AUTOSAR XML (schema 4-0-3)
package /ComponentTypes
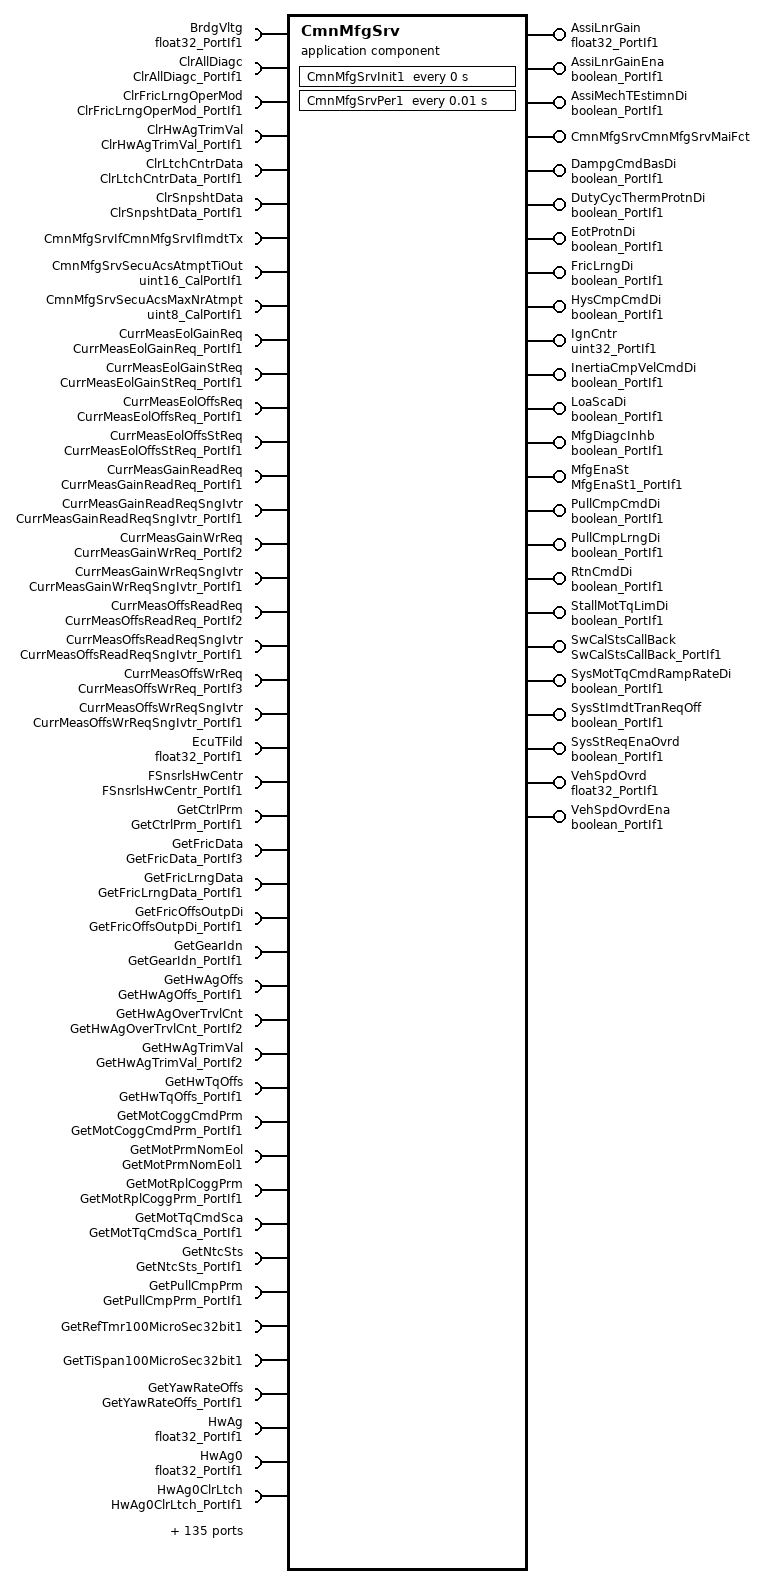
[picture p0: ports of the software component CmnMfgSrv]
  application sw component type CmnMfgSrv
    24 x provide port:
      AssiLnrGain: nonqueued-sender-com-spec{data-element=Val, init-value=0}, provided-interface=float32_PortIf1
      AssiLnrGainEna: nonqueued-sender-com-spec{data-element=Logl, init-value=0}, provided-interface=boolean_PortIf1
      AssiMechTEstimnDi: nonqueued-sender-com-spec{data-element=Logl, init-value=0}, provided-interface=boolean_PortIf1
      CmnMfgSrvCmnMfgSrvMaiFct: server-com-spec{operation=Oper, queue-length=1}, provided-interface=CmnMfgSrvCmnMfgSrvMaiFct
      DampgCmdBasDi: nonqueued-sender-com-spec{data-element=Logl, init-value=0}, provided-interface=boolean_PortIf1
      DutyCycThermProtnDi: nonqueued-sender-com-spec{data-element=Logl, init-value=0}, provided-interface=boolean_PortIf1
      EotProtnDi: nonqueued-sender-com-spec{data-element=Logl, init-value=0}, provided-interface=boolean_PortIf1
      FricLrngDi: nonqueued-sender-com-spec{data-element=Logl, init-value=0}, provided-interface=boolean_PortIf1
      HysCmpCmdDi: nonqueued-sender-com-spec{data-element=Logl, init-value=0}, provided-interface=boolean_PortIf1
      IgnCntr: nonqueued-sender-com-spec{data-element=Val, init-value=0}, provided-interface=uint32_PortIf1
      InertiaCmpVelCmdDi: nonqueued-sender-com-spec{data-element=Logl, init-value=0}, provided-interface=boolean_PortIf1
      LoaScaDi: nonqueued-sender-com-spec{data-element=Logl, init-value=0}, provided-interface=boolean_PortIf1
      MfgDiagcInhb: nonqueued-sender-com-spec{data-element=Logl, init-value=0}, provided-interface=boolean_PortIf1
      MfgEnaSt: nonqueued-sender-com-spec{data-element=Val, init-value=0}, provided-interface=MfgEnaSt1_PortIf1
      PullCmpCmdDi: nonqueued-sender-com-spec{data-element=Logl, init-value=0}, provided-interface=boolean_PortIf1
      PullCmpLrngDi: nonqueued-sender-com-spec{data-element=Logl, init-value=0}, provided-interface=boolean_PortIf1
      RtnCmdDi: nonqueued-sender-com-spec{data-element=Logl, init-value=0}, provided-interface=boolean_PortIf1
      StallMotTqLimDi: nonqueued-sender-com-spec{data-element=Logl, init-value=0}, provided-interface=boolean_PortIf1
      SwCalStsCallBack: server-com-spec{operation=Oper, queue-length=1}, provided-interface=SwCalStsCallBack_PortIf1
      SysMotTqCmdRampRateDi: nonqueued-sender-com-spec{data-element=Logl, init-value=0}, provided-interface=boolean_PortIf1
      SysStImdtTranReqOff: nonqueued-sender-com-spec{data-element=Logl, init-value=0}, provided-interface=boolean_PortIf1
      SysStReqEnaOvrd: nonqueued-sender-com-spec{data-element=Logl, init-value=0}, provided-interface=boolean_PortIf1
      VehSpdOvrd: nonqueued-sender-com-spec{data-element=Val, init-value=0}, provided-interface=float32_PortIf1
      VehSpdOvrdEna: nonqueued-sender-com-spec{data-element=Logl, init-value=0}, provided-interface=boolean_PortIf1
    183 x require port:
      BrdgVltg: nonqueued-receiver-com-spec{data-element=Val, filter=data-filter-type=ALWAYS, init-value=6}, required-interface=float32_PortIf1
      ClrAllDiagc: client-com-spec=Oper, required-interface=ClrAllDiagc_PortIf1
      ClrFricLrngOperMod: client-com-spec=Oper, required-interface=ClrFricLrngOperMod_PortIf1
      ClrHwAgTrimVal: client-com-spec=Oper, required-interface=ClrHwAgTrimVal_PortIf1
      ClrLtchCntrData: client-com-spec=Oper, required-interface=ClrLtchCntrData_PortIf1
      ClrSnpshtData: client-com-spec=Oper, required-interface=ClrSnpshtData_PortIf1
      CmnMfgSrvIfCmnMfgSrvIfImdtTx: client-com-spec=Oper, required-interface=CmnMfgSrvIfCmnMfgSrvIfImdtTx
      CmnMfgSrvSecuAcsAtmptTiOut: parameter-require-com-spec{init-value=10000, parameter=Val}, required-interface=uint16_CalPortIf1
      CmnMfgSrvSecuAcsMaxNrAtmpt: parameter-require-com-spec{init-value=2, parameter=Val}, required-interface=uint8_CalPortIf1
      CurrMeasEolGainReq: client-com-spec=Oper, required-interface=CurrMeasEolGainReq_PortIf1
      CurrMeasEolGainStReq: client-com-spec=Oper, required-interface=CurrMeasEolGainStReq_PortIf1
      CurrMeasEolOffsReq: client-com-spec=Oper, required-interface=CurrMeasEolOffsReq_PortIf1
      CurrMeasEolOffsStReq: client-com-spec=Oper, required-interface=CurrMeasEolOffsStReq_PortIf1
      CurrMeasGainReadReq: client-com-spec=Oper, required-interface=CurrMeasGainReadReq_PortIf1
      CurrMeasGainReadReqSngIvtr: client-com-spec=Oper, required-interface=CurrMeasGainReadReqSngIvtr_PortIf1
      CurrMeasGainWrReq: client-com-spec=Oper, required-interface=CurrMeasGainWrReq_PortIf2
      CurrMeasGainWrReqSngIvtr: client-com-spec=Oper, required-interface=CurrMeasGainWrReqSngIvtr_PortIf1
      CurrMeasOffsReadReq: client-com-spec=Oper, required-interface=CurrMeasOffsReadReq_PortIf2
      CurrMeasOffsReadReqSngIvtr: client-com-spec=Oper, required-interface=CurrMeasOffsReadReqSngIvtr_PortIf1
      CurrMeasOffsWrReq: client-com-spec=Oper, required-interface=CurrMeasOffsWrReq_PortIf3
      CurrMeasOffsWrReqSngIvtr: client-com-spec=Oper, required-interface=CurrMeasOffsWrReqSngIvtr_PortIf1
      EcuTFild: nonqueued-receiver-com-spec{data-element=Val, filter=data-filter-type=ALWAYS, init-value=25}, required-interface=float32_PortIf1
      FSnsrlsHwCentr: client-com-spec=Oper, required-interface=FSnsrlsHwCentr_PortIf1
      GetCtrlPrm: client-com-spec=Oper, required-interface=GetCtrlPrm_PortIf1
      GetFricData: client-com-spec=Oper, required-interface=GetFricData_PortIf3
      GetFricLrngData: client-com-spec=Oper, required-interface=GetFricLrngData_PortIf1
      GetFricOffsOutpDi: client-com-spec=Oper, required-interface=GetFricOffsOutpDi_PortIf1
      GetGearIdn: client-com-spec=Oper, required-interface=GetGearIdn_PortIf1
      GetHwAgOffs: client-com-spec=Oper, required-interface=GetHwAgOffs_PortIf1
      GetHwAgOverTrvlCnt: client-com-spec=Oper, required-interface=GetHwAgOverTrvlCnt_PortIf2
      GetHwAgTrimVal: client-com-spec=Oper, required-interface=GetHwAgTrimVal_PortIf2
      GetHwTqOffs: client-com-spec=Oper, required-interface=GetHwTqOffs_PortIf1
      GetMotCoggCmdPrm: client-com-spec=Oper, required-interface=GetMotCoggCmdPrm_PortIf1
      GetMotPrmNomEol: client-com-spec=Oper, required-interface=GetMotPrmNomEol1
      GetMotRplCoggPrm: client-com-spec=Oper, required-interface=GetMotRplCoggPrm_PortIf1
      GetMotTqCmdSca: client-com-spec=Oper, required-interface=GetMotTqCmdSca_PortIf1
      GetNtcSts: client-com-spec=Oper, required-interface=GetNtcSts_PortIf1
      GetPullCmpPrm: client-com-spec=Oper, required-interface=GetPullCmpPrm_PortIf1
      GetRefTmr100MicroSec32bit1: client-com-spec=Oper, required-interface=GetRefTmr100MicroSec32bit1
      GetTiSpan100MicroSec32bit1: client-com-spec=Oper, required-interface=GetTiSpan100MicroSec32bit1
      GetYawRateOffs: client-com-spec=Oper, required-interface=GetYawRateOffs_PortIf1
      HwAg: nonqueued-receiver-com-spec{data-element=Val, filter=data-filter-type=ALWAYS, init-value=0}, required-interface=float32_PortIf1
      HwAg0: nonqueued-receiver-com-spec{data-element=Val, filter=data-filter-type=ALWAYS, init-value=0}, required-interface=float32_PortIf1
      HwAg0ClrLtch: client-com-spec=Oper, required-interface=HwAg0ClrLtch_PortIf1
      HwAg0MeasHwAg0AutoTrim: client-com-spec=Oper, required-interface=HwAg0MeasHwAg0AutoTrim1
      HwAg0MeasHwAg0ClrTrim: client-com-spec=Oper, required-interface=HwAg0MeasHwAg0ClrTrim1
      HwAg0MeasHwAg0ReadTrim: client-com-spec=Oper, required-interface=HwAg0MeasHwAg0ReadTrim2
      HwAg0MeasHwAg0TrimPrfmdSts: client-com-spec=Oper, required-interface=HwAg0MeasHwAg0TrimPrfmdSts2
      HwAg0MeasHwAg0WrTrim: client-com-spec=Oper, required-interface=HwAg0MeasHwAg0WrTrim2
      HwAg1: nonqueued-receiver-com-spec{data-element=Val, filter=data-filter-type=ALWAYS, init-value=0}, required-interface=float32_PortIf1
      HwAg1ClrLtch: client-com-spec=Oper, required-interface=HwAg1ClrLtch_PortIf1
      HwAg1MeasHwAg1AutoTrim: client-com-spec=Oper, required-interface=HwAg1MeasHwAg1AutoTrim1
      HwAg1MeasHwAg1ClrTrim: client-com-spec=Oper, required-interface=HwAg1MeasHwAg1ClrTrim1
      HwAg1MeasHwAg1ReadTrim: client-com-spec=Oper, required-interface=HwAg1MeasHwAg1ReadTrim2
      HwAg1MeasHwAg1TrimPrfmdSts: client-com-spec=Oper, required-interface=HwAg1MeasHwAg1TrimPrfmdSts2
      HwAg1MeasHwAg1WrTrim: client-com-spec=Oper, required-interface=HwAg1MeasHwAg1WrTrim2
      HwTq: nonqueued-receiver-com-spec{data-element=Val, filter=data-filter-type=ALWAYS, init-value=0}, required-interface=float32_PortIf1
      HwTq0: nonqueued-receiver-com-spec{data-element=Val, filter=data-filter-type=ALWAYS, init-value=0}, required-interface=float32_PortIf1
      HwTq0MeasHwTq0AutTrim: client-com-spec=Oper, required-interface=HwTq0MeasHwTq0AutTrim_PortIf1
      HwTq0MeasHwTq0ClrTrim: client-com-spec=Oper, required-interface=HwTq0MeasHwTq0ClrTrim_PortIf1
      HwTq0MeasHwTq0ReadTrim: client-com-spec=Oper, required-interface=HwTq0MeasHwTq0ReadTrim_PortIf1
      HwTq0MeasHwTq0TrimPrfmdSts: client-com-spec=Oper, required-interface=HwTq0MeasHwTq0TrimPrfmdSts_PortIf1
      HwTq0MeasHwTq0WrTrim: client-com-spec=Oper, required-interface=HwTq0MeasHwTq0WrTrim_PortIf1
      HwTq1: nonqueued-receiver-com-spec{data-element=Val, filter=data-filter-type=ALWAYS, init-value=0}, required-interface=float32_PortIf1
      HwTq1MeasHwTq1AutTrim: client-com-spec=Oper, required-interface=HwTq1MeasHwTq1AutTrim_PortIf1
      HwTq1MeasHwTq1ClrTrim: client-com-spec=Oper, required-interface=HwTq1MeasHwTq1ClrTrim_PortIf1
      HwTq1MeasHwTq1ReadTrim: client-com-spec=Oper, required-interface=HwTq1MeasHwTq1ReadTrim_PortIf1
      HwTq1MeasHwTq1TrimPrfmdSts: client-com-spec=Oper, required-interface=HwTq1MeasHwTq1TrimPrfmdSts_PortIf1
      HwTq1MeasHwTq1WrTrim: client-com-spec=Oper, required-interface=HwTq1MeasHwTq1WrTrim_PortIf1
      HwTq2: nonqueued-receiver-com-spec{data-element=Val, filter=data-filter-type=ALWAYS, init-value=0}, required-interface=float32_PortIf1
      HwTq2MeasHwTq2AutTrim: client-com-spec=Oper, required-interface=HwTq2MeasHwTq2AutTrim_PortIf1
      HwTq2MeasHwTq2ClrTrim: client-com-spec=Oper, required-interface=HwTq2MeasHwTq2ClrTrim_PortIf1
      HwTq2MeasHwTq2ReadTrim: client-com-spec=Oper, required-interface=HwTq2MeasHwTq2ReadTrim_PortIf1
      HwTq2MeasHwTq2TrimPrfmdSts: client-com-spec=Oper, required-interface=HwTq2MeasHwTq2TrimPrfmdSts_PortIf1
      HwTq2MeasHwTq2WrTrim: client-com-spec=Oper, required-interface=HwTq2MeasHwTq2WrTrim_PortIf1
      HwTq3: nonqueued-receiver-com-spec{data-element=Val, filter=data-filter-type=ALWAYS, init-value=0}, required-interface=float32_PortIf1
      HwTq3MeasHwTq3AutTrim: client-com-spec=Oper, required-interface=HwTq3MeasHwTq3AutTrim_PortIf1
      HwTq3MeasHwTq3ClrTrim: client-com-spec=Oper, required-interface=HwTq3MeasHwTq3ClrTrim_PortIf1
      HwTq3MeasHwTq3ReadTrim: client-com-spec=Oper, required-interface=HwTq3MeasHwTq3ReadTrim_PortIf1
      HwTq3MeasHwTq3TrimPrfmdSts: client-com-spec=Oper, required-interface=HwTq3MeasHwTq3TrimPrfmdSts_PortIf1
      HwTq3MeasHwTq3WrTrim: client-com-spec=Oper, required-interface=HwTq3MeasHwTq3WrTrim_PortIf1
      HwTq4AutTrim: client-com-spec=Oper, required-interface=HwTqMeasHwTqAutTrim_PortIf1
      HwTq4ClrSnsrSca: client-com-spec=Oper, required-interface=HwTqClrSnsrSca_PortIf1
      HwTq4ClrTrim: client-com-spec=Oper, required-interface=HwTqMeasHwTqClrTrim_PortIf1
      HwTq4ReadSnsrSca: client-com-spec=Oper, required-interface=HwTqReadSnsrSca_PortIf2
      HwTq4ReadTrim: client-com-spec=Oper, required-interface=HwTqMeasHwTqReadTrim_PortIf1
      HwTq4SnsrScaPrfmdSts: client-com-spec=Oper, required-interface=HwTqSnsrScaPrfmdSts_PortIf1
      HwTq4TrimPrfmdSts: client-com-spec=Oper, required-interface=HwTqMeasHwTqTrimPrfmdSts_PortIf1
      HwTq4WrSnsrSca: client-com-spec=Oper, required-interface=HwTqWrSnsrSca_PortIf1
      HwTq4WrTrim: client-com-spec=Oper, required-interface=HwTqMeasHwTqWrTrim_PortIf1
      HwTq5AutTrim: client-com-spec=Oper, required-interface=HwTqMeasHwTqAutTrim_PortIf1
      HwTq5ClrSnsrSca: client-com-spec=Oper, required-interface=HwTqClrSnsrSca_PortIf1
      HwTq5ClrTrim: client-com-spec=Oper, required-interface=HwTqMeasHwTqClrTrim_PortIf1
      HwTq5ReadSnsrSca: client-com-spec=Oper, required-interface=HwTqReadSnsrSca_PortIf2
      HwTq5ReadTrim: client-com-spec=Oper, required-interface=HwTqMeasHwTqReadTrim_PortIf1
      HwTq5SnsrScaPrfmdSts: client-com-spec=Oper, required-interface=HwTqSnsrScaPrfmdSts_PortIf1
      HwTq5TrimPrfmdSts: client-com-spec=Oper, required-interface=HwTqMeasHwTqTrimPrfmdSts_PortIf1
      HwTq5WrSnsrSca: client-com-spec=Oper, required-interface=HwTqWrSnsrSca_PortIf1
      HwTq5WrTrim: client-com-spec=Oper, required-interface=HwTqMeasHwTqWrTrim_PortIf1
      InitFricLrngTbl: client-com-spec=Oper, required-interface=InitFricLrngTbl_PortIf1
      MotAg0MeasMotAg0CoeffTblRead: client-com-spec=Oper, required-interface=MotAgMeasMotAgCoeffTblRead_PortIf1
      MotAg0MeasMotAg0CoeffTblWr: client-com-spec=Oper, required-interface=MotAgMeasMotAgCoeffTblWr_PortIf1
      MotAg0Mecl: nonqueued-receiver-com-spec{data-element=Val, filter=data-filter-type=ALWAYS, init-value=0}, required-interface=uint16_PortIf1
      MotAg1MeasMotAg1CoeffTblRead: client-com-spec=Oper, required-interface=MotAgMeasMotAgCoeffTblRead_PortIf1
      MotAg1MeasMotAg1CoeffTblWr: client-com-spec=Oper, required-interface=MotAgMeasMotAgCoeffTblWr_PortIf1
      MotAg1Mecl: nonqueued-receiver-com-spec{data-element=Val, filter=data-filter-type=ALWAYS, init-value=0}, required-interface=uint16_PortIf1
      MotAg2Mecl: nonqueued-receiver-com-spec{data-element=Val, filter=data-filter-type=ALWAYS, init-value=0}, required-interface=uint16_PortIf1
      MotAg5EolPrmRead: client-com-spec=Oper, required-interface=MotAgEolPrmRead_PortIf1
      MotAg5EolPrmWr: client-com-spec=Oper, required-interface=MotAgEolPrmWr_PortIf1
      MotAg6EolPrmRead: client-com-spec=Oper, required-interface=MotAgEolPrmRead_PortIf1
      MotAg6EolPrmWr: client-com-spec=Oper, required-interface=MotAgEolPrmWr_PortIf1
      MotAgCmpBackEmfRead: client-com-spec=Oper, required-interface=MotAgCmpBackEmfRead1
      MotAgCmpBackEmfWr: client-com-spec=Oper, required-interface=MotAgCmpBackEmfWr1
      MotAgCumvAlgndMrf: nonqueued-receiver-com-spec{data-element=Val, filter=data-filter-type=ALWAYS, init-value=0}, required-interface=sint32_PortIf1
      MotAgMeasEolPrmRead: client-com-spec=Oper, required-interface=MotAgMeasEolPrmRead_PortIf2
      MotAgMeasEolPrmWr: client-com-spec=Oper, required-interface=MotAgMeasEolPrmWr_PortIf2
      MotAgMecl: nonqueued-receiver-com-spec{data-element=Val, filter=data-filter-type=ALWAYS, init-value=0}, required-interface=uint16_PortIf1
      MotCurrDax: nonqueued-receiver-com-spec{data-element=Val, filter=data-filter-type=ALWAYS, init-value=0}, required-interface=float32_PortIf1
      MotCurrQax: nonqueued-receiver-com-spec{data-element=Val, filter=data-filter-type=ALWAYS, init-value=0}, required-interface=float32_PortIf1
      MotTqCmd: nonqueued-receiver-com-spec{data-element=Val, filter=data-filter-type=ALWAYS, init-value=0}, required-interface=float32_PortIf1
      MotVelMrf: nonqueued-receiver-com-spec{data-element=Val, filter=data-filter-type=ALWAYS, init-value=0}, required-interface=float32_PortIf1
      NvmCcaHwPartNr: required-com-specs=[EraseBlock, GetErrorStatus, InvalidateNvBlock, ReadBlock, SetRamBlockStatus, WriteBlock], required-interface=NvMService_AC3_SRBS
      NvmCcaSerlNr: required-com-specs=[EraseBlock, GetErrorStatus, InvalidateNvBlock, ReadBlock, SetRamBlockStatus, WriteBlock], required-interface=NvMService_AC3_SRBS
      NvmDiRestore: required-com-specs=[EraseBlock, GetErrorStatus, InvalidateNvBlock, ReadBlock, SetRamBlockStatus, WriteBlock], required-interface=NvMService_AC3_SRBS
      NvmEpsSysSerlNr: required-com-specs=[EraseBlock, GetErrorStatus, InvalidateNvBlock, ReadBlock, SetRamBlockStatus, WriteBlock], required-interface=NvMService_AC3_SRBS
      NvmIgnCntr: required-com-specs=[EraseBlock, GetErrorStatus, InvalidateNvBlock, ReadBlock, SetRamBlockStatus, WriteBlock], required-interface=NvMService_AC3_SRBS
      NvmMfgEnaCntr: required-com-specs=[EraseBlock, GetErrorStatus, InvalidateNvBlock, ReadBlock, SetRamBlockStatus, WriteBlock], required-interface=NvMService_AC3_SRBS
      NvmMfgTmpBuf{0..4}: required-com-specs=[EraseBlock, GetErrorStatus, InvalidateNvBlock, ReadBlock, SetRamBlockStatus, WriteBlock], required-interface=NvMService_AC3_SRBS
      NvmSeedKey: required-com-specs=[EraseBlock, GetErrorStatus, InvalidateNvBlock, ReadBlock, RestoreBlockDefaults, SetRamBlockStatus, WriteBlock], required-interface=NvMService_AC3_SRBS_Defs
      NxtrCalIdsCalDevlpRd: client-com-spec=Oper, required-interface=NxtrCalIdsCalDevlpRd_PortIf1
      NxtrCalIdsCalRelRd: client-com-spec=Oper, required-interface=NxtrCalIdsCalRelRd_PortIf1
      NxtrSwIdsPsrInfoRd: client-com-spec=Oper, required-interface=NxtrSwIdsPsrInfoRd_PortIf1
      NxtrSwIdsSwBuildDateTiRd: client-com-spec=Oper, required-interface=NxtrSwIdsSwBuildDateTiRd_PortIf1
      NxtrSwIdsSwRelInfoRd: client-com-spec=Oper, required-interface=NxtrSwIdsSwRelInfoRd_PortIf1
      NxtrSwIdsSwRelNrRd: client-com-spec=Oper, required-interface=NxtrSwIdsSwRelNrRd_PortIf1
      NxtrSwIdsSwRelVerRd: client-com-spec=Oper, required-interface=NxtrSwIdsSwRelVerRd_PortIf1
      PinionAg: nonqueued-receiver-com-spec{data-element=Val, filter=data-filter-type=ALWAYS, init-value=0}, required-interface=float32_PortIf1
      PolarityCfgRead: client-com-spec=Oper, required-interface=PolarityCfgRead1
      PolarityCfgWr: client-com-spec=Oper, required-interface=PolarityCfgWr1
      ReadExtdSnpshtData: client-com-spec=Oper, required-interface=ReadSnpshtData_PortIf2
      ReadLtchCntrData: client-com-spec=Oper, required-interface=ReadLtchCntrData_PortIf1
      ReadNtcFltAry: client-com-spec=Oper, required-interface=ReadNtcFltAry_PortIf1
      ReadNtcInfoAndDebCntr: client-com-spec=Oper, required-interface=ReadNtcInfoAndDebCntr_PortIf1
      ReadSnpshtData: client-com-spec=Oper, required-interface=ReadSnpshtData_PortIf1
      RstHwAgOverTrvlCnt: client-com-spec=Oper, required-interface=RstHwAgOverTrvlCnt_PortIf1
      RstHwTq: client-com-spec=Oper, required-interface=RstHwTq_PortIf1
      RstMaxHwAgCwAndCcw: client-com-spec=Oper, required-interface=RstMaxHwAgCwAndCcw_PortIf1
      RstPullCmp: client-com-spec=Oper, required-interface=RstPullCmp_PortIf1
      RstSnsrlsHwCentr: client-com-spec=Oper, required-interface=RstSnsrlsHwCentr_PortIf1
      RstYawAndAg: client-com-spec=Oper, required-interface=RstYawAndAg_PortIf1
      RtnMaxHwAgCwAndCcw: client-com-spec=Oper, required-interface=RtnMaxHwAgCwAndCcw_PortIf1
      SerlComRstEot: client-com-spec=Oper, required-interface=SerlComRstEot_PortIf1
      SetCtrlPrm: client-com-spec=Oper, required-interface=SetCtrlPrm_PortIf1
      SetFricData: client-com-spec=Oper, required-interface=SetFricData_PortIf3
      SetFricLrngData: client-com-spec=Oper, required-interface=SetFricLrngData_PortIf1
      SetFricOffsOutpDi: client-com-spec=Oper, required-interface=SetFricOffsOutpDi_PortIf1
      SetHwAgOffs: client-com-spec=Oper, required-interface=SetHwAgOffs_PortIf1
      SetHwAgOverTrvlCnt: client-com-spec=Oper, required-interface=SetHwAgOverTrvlCnt_PortIf2
      SetHwAgTrimVal: client-com-spec=Oper, required-interface=SetHwAgTrimVal_PortIf2
      SetHwTqOffs: client-com-spec=Oper, required-interface=SetHwTqOffs_PortIf1
      SetManTqCmd: client-com-spec=Oper, required-interface=SetManTqCmd1
      SetMotCoggCmdPrm: client-com-spec=Oper, required-interface=SetMotCoggCmdPrm_PortIf1
      SetMotPrmNomEol: client-com-spec=Oper, required-interface=SetMotPrmNomEol1
      SetMotRplCoggPrm: client-com-spec=Oper, required-interface=SetMotRplCoggPrm_PortIf1
      SetMotTqCmdSca: client-com-spec=Oper, required-interface=SetMotTqCmdSca_PortIf1
      SetPullCmpLongTerm: client-com-spec=Oper, required-interface=SetPullCmpLongTerm_PortIf1
      SetPullCmpShoTerm: client-com-spec=Oper, required-interface=SetPullCmpShoTerm_PortIf1
      SetYawRateOffs: client-com-spec=Oper, required-interface=SetYawRateOffs_PortIf1
      StackMeasClr: client-com-spec=Oper, required-interface=StackMeasClr_PortIf1
      StackMeasRead: client-com-spec=Operation, required-interface=StackMeasRead_PortIf1
      StopCtrl: client-com-spec=Oper, required-interface=StopCtrl_PortIf1
      StrtCtrl: client-com-spec=Oper, required-interface=StrtCtrl_PortIf1
      SwCalGetPrm: client-com-spec=Oper, required-interface=SwCalGetPrm_PortIf1
      SwCalSetPrm: client-com-spec=Oper, required-interface=SwCalSetPrm_PortIf1
      SwCalStop: client-com-spec=Oper, required-interface=SwCalStop_PortIf1
      SwCalStrt: client-com-spec=Oper, required-interface=SwCalStrt_PortIf1
      SysSt: nonqueued-receiver-com-spec{data-element=Val, filter=data-filter-type=ALWAYS, init-value=3}, required-interface=SysSt1
      UpdErrInjReg: client-com-spec=Oper, required-interface=UpdErrInjReg_PortIf1
      UpdHwAgTrimVal: client-com-spec=Oper, required-interface=UpdHwAgTrimVal_PortIf1
    behavior CmnMfgSrv_InternalBehavior: data-type-mapping=Nexteer
      ar-typed-per-instance-memorys:
        41 x data, all with sw-calibration-access=READ-ONLY:
          CcaHwPartNr: type=Ary1D_u8_20
          CcaSerlNr: type=Ary1D_u8_20
          DiAssiMechTEstimn: type=boolean
          DiDampg: type=boolean
          DiDutyCycThermProtn: type=boolean
          DiEotProtn: type=boolean
          DiHysCmp: type=boolean
          DiInertiaCmp: type=boolean
          DiLoaSca: type=boolean
          DiPullCmpActvCmd: type=boolean
          DiPullCmpActvLrng: type=boolean
          DiRestore: type=Ary1D_u8_8
          DiRtn: type=boolean
          DiStallMotTqLim: type=boolean
          DiSysFricLrng: type=boolean
          DiSysMotTqCmdRampRate: type=boolean
          EpsSysSerlNr: type=Ary1D_u8_20
          IgnCntr: type=uint32
          InpOutpCtrlAssiGain: type=float32
          InpOutpCtrlVehSpdOvrd: type=float32
          MfgDiagcInhb: type=boolean
          MfgTmpBuf{0..4}: type=Ary1D_u8_16
          NxtrMfgEnaCntr: type=uint8
          PerCyc: type=uint16
          PerDivdr: type=uint16
          PerPidTbl: type=Ary1D_u16_16
          PerPidTblLen: type=uint8
          PerRunng: type=boolean
          ReqLen: type=uint16
          SecuAcsAtmptCntr: type=uint8
          SecuAcsAtmptTmr: type=uint32
          SecuAcsSeedReqCmpl: type=boolean
          SecuAcsUnlckd: type=boolean
          SeedKey: type=Ary1D_u32_2
          SessionCurr: type=uint8
          SessionTiOut: type=uint32
          SysStReqEnaOvrd: type=boolean
      operation invoked event OIT_CmnMfgSrvCmnMfgSrvMaiHndl_Oper_CmnMfgSrvCmnMfgSrvMaiHndl_Oper: start-on-event=CmnMfgSrvCmnMfgSrvMaiFct_Oper, operation=CmnMfgSrvCmnMfgSrvMaiFct.Oper
      timing event CmnMfgSrv_InitEvent: start-on-event=CmnMfgSrvInit1, period=0
      timing event TMT_CmnMfgSrvPer1: start-on-event=CmnMfgSrvPer1, period=0.01
      operation invoked event OIT_SwCalStsCallBack_Oper_SwCalStsCallBack_Oper: start-on-event=SwCalStsCallBack_Oper, operation=SwCalStsCallBack.Oper
      port-api-options:
        enable-take-address=false, indirect-api=false, port=AssiLnrGain
        enable-take-address=false, indirect-api=false, port=CurrMeasOffsWrReq
        enable-take-address=false, indirect-api=false, port=GetFricData
        enable-take-address=false, indirect-api=false, port=GetFricLrngData
        enable-take-address=false, indirect-api=false, port=GetFricOffsOutpDi
        enable-take-address=false, indirect-api=false, port=GetGearIdn
        enable-take-address=false, indirect-api=false, port=NvmMfgTmpBuf4
        enable-take-address=false, indirect-api=false, port=NvmSeedKey
        enable-take-address=false, indirect-api=false, port=NxtrCalIdsCalDevlpRd
        enable-take-address=false, indirect-api=false, port=NxtrCalIdsCalRelRd
        enable-take-address=false, indirect-api=false, port=NxtrSwIdsPsrInfoRd
        enable-take-address=false, indirect-api=false, port=NxtrSwIdsSwBuildDateTiRd
        enable-take-address=false, indirect-api=false, port=NxtrSwIdsSwRelInfoRd
        enable-take-address=false, indirect-api=false, port=NxtrSwIdsSwRelNrRd
        enable-take-address=false, indirect-api=false, port=NxtrSwIdsSwRelVerRd
        enable-take-address=false, indirect-api=false, port=PinionAg
        enable-take-address=false, indirect-api=false, port=PolarityCfgRead
        enable-take-address=false, indirect-api=false, port=PolarityCfgWr
        enable-take-address=false, indirect-api=false, port=PullCmpCmdDi
        enable-take-address=false, indirect-api=false, port=PullCmpLrngDi
        enable-take-address=false, indirect-api=false, port=ReadNtcFltAry
        enable-take-address=false, indirect-api=false, port=ReadNtcInfoAndDebCntr
        enable-take-address=false, indirect-api=false, port=ReadSnpshtData
        enable-take-address=false, indirect-api=false, port=RstHwAgOverTrvlCnt
        enable-take-address=false, indirect-api=false, port=RstHwTq
        enable-take-address=false, indirect-api=false, port=RstMaxHwAgCwAndCcw
        enable-take-address=false, indirect-api=false, port=RstPullCmp
        enable-take-address=false, indirect-api=false, port=RstSnsrlsHwCentr
        enable-take-address=false, indirect-api=false, port=RstYawAndAg
        enable-take-address=false, indirect-api=false, port=RtnCmdDi
        enable-take-address=false, indirect-api=false, port=RtnMaxHwAgCwAndCcw
        enable-take-address=false, indirect-api=false, port=SerlComRstEot
        enable-take-address=false, indirect-api=false, port=SetCtrlPrm
        enable-take-address=false, indirect-api=false, port=SetFricData
        enable-take-address=false, indirect-api=false, port=SetFricLrngData
        enable-take-address=false, indirect-api=false, port=SetFricOffsOutpDi
        enable-take-address=false, indirect-api=false, port=SetHwAgOffs
        enable-take-address=false, indirect-api=false, port=SetHwAgOverTrvlCnt
        enable-take-address=false, indirect-api=false, port=SetHwAgTrimVal
        enable-take-address=false, indirect-api=false, port=SetHwTqOffs
        enable-take-address=false, indirect-api=false, port=SetManTqCmd
        enable-take-address=false, indirect-api=false, port=SetYawRateOffs
        enable-take-address=false, indirect-api=false, port=StackMeasClr
        enable-take-address=false, indirect-api=false, port=StackMeasRead
        enable-take-address=false, indirect-api=false, port=StallMotTqLimDi
        enable-take-address=false, indirect-api=false, port=StopCtrl
        enable-take-address=false, indirect-api=false, port=SwCalStrt
        enable-take-address=false, indirect-api=false, port=SwCalStsCallBack
        enable-take-address=false, indirect-api=false, port=UpdErrInjReg
        enable-take-address=false, indirect-api=false, port=UpdHwAgTrimVal
        enable-take-address=false, indirect-api=false, port=VehSpdOvrdEna
      4 x runnable:
        CmnMfgSrvCmnMfgSrvMaiFct_Oper
          data-receive-point-by-arguments:
            21 x access:
              REC_BrdgVltg_Val: accessed-variable=BrdgVltg.Val
              REC_EcuTFild_Val: accessed-variable=EcuTFild.Val
              REC_HwAg_Val: accessed-variable=HwAg.Val
              REC_HwAg0_Val: accessed-variable=HwAg0.Val
              REC_HwAg1_Val: accessed-variable=HwAg1.Val
              REC_HwTq_Val: accessed-variable=HwTq.Val
              REC_HwTq{0..3}_Val: accessed-variable=HwTq{0..3}.Val
              REC_MotAg{0..2}Mecl_Val: accessed-variable=MotAg{0..2}Mecl.Val
              REC_MotAgCumvAlgndMrf_Val: accessed-variable=MotAgCumvAlgndMrf.Val
              REC_MotAgMecl_Val: accessed-variable=MotAgMecl.Val
              REC_MotCurrDax_Val: accessed-variable=MotCurrDax.Val
              REC_MotCurrQax_Val: accessed-variable=MotCurrQax.Val
              REC_MotTqCmd_Val: accessed-variable=MotTqCmd.Val
              REC_MotVelMrf_Val: accessed-variable=MotVelMrf.Val
              REC_PinionAg_Val: accessed-variable=PinionAg.Val
              REC_SysSt_Val: accessed-variable=SysSt.Val
          data-send-points:
            7 x access:
              SEND_AssiLnrGain_Val: accessed-variable=AssiLnrGain.Val
              SEND_AssiLnrGainEna_Logl: accessed-variable=AssiLnrGainEna.Logl
              SEND_IgnCntr_Val_1: accessed-variable=IgnCntr.Val
              SEND_MfgEnaSt_Val: accessed-variable=MfgEnaSt.Val
              SEND_SysStImdtTranReqOff_Logl: accessed-variable=SysStImdtTranReqOff.Logl
              SEND_VehSpdOvrdEna_Logl: accessed-variable=VehSpdOvrdEna.Logl
              SEND_VehSpdOvrdVal_Val: accessed-variable=VehSpdOvrd.Val
          161 x sync call, all with timeout=0:
            SC_ClrAllDiagc_Oper: operation=ClrAllDiagc.Oper
            SC_ClrFricLrngOperMod_Oper: operation=ClrFricLrngOperMod.Oper
            SC_ClrHwAgTrimVal_Oper: operation=ClrHwAgTrimVal.Oper
            SC_ClrLtchCntrData_Oper: operation=ClrLtchCntrData.Oper
            SC_ClrSnpshtData_Oper: operation=ClrSnpshtData.Oper
            SC_CurrMeasEolGainReq_Oper_1: operation=CurrMeasEolGainReq.Oper
            SC_CurrMeasEolGainStReq_Oper_1: operation=CurrMeasEolGainStReq.Oper
            SC_CurrMeasEolOffsReq_Oper_1: operation=CurrMeasEolOffsReq.Oper
            SC_CurrMeasEolOffsStReq_Oper_1: operation=CurrMeasEolOffsStReq.Oper
            SC_CurrMeasGainReadReq_Oper: operation=CurrMeasGainReadReq.Oper
            SC_CurrMeasGainReadReqSngIvtr_Oper: operation=CurrMeasGainReadReqSngIvtr.Oper
            SC_CurrMeasGainWrReq_Oper_1: operation=CurrMeasGainWrReq.Oper
            SC_CurrMeasGainWrReqSngIvtr_Oper: operation=CurrMeasGainWrReqSngIvtr.Oper
            SC_CurrMeasOffsReadReq_Oper: operation=CurrMeasOffsReadReq.Oper
            SC_CurrMeasOffsReadReqSngIvtr_Oper: operation=CurrMeasOffsReadReqSngIvtr.Oper
            SC_CurrMeasOffsWrReq_Oper_1: operation=CurrMeasOffsWrReq.Oper
            SC_CurrMeasOffsWrReqSngIvtr_Oper: operation=CurrMeasOffsWrReqSngIvtr.Oper
            SC_FSnsrlsHwCentr_Oper: operation=FSnsrlsHwCentr.Oper
            SC_GetCtrlPrm_Oper: operation=GetCtrlPrm.Oper
            SC_GetFricData_Oper: operation=GetFricData.Oper
            SC_GetFricLrngData_Oper: operation=GetFricLrngData.Oper
            SC_GetFricOffsOutpDi_Oper: operation=GetFricOffsOutpDi.Oper
            SC_GetGearIdn_Oper: operation=GetGearIdn.Oper
            SC_GetHwAgOffs_Oper: operation=GetHwAgOffs.Oper
            SC_GetHwAgOverTrvlCnt_Oper: operation=GetHwAgOverTrvlCnt.Oper
            SC_GetHwAgTrimVal_Oper_1: operation=GetHwAgTrimVal.Oper
            SC_GetHwTqOffs_Oper: operation=GetHwTqOffs.Oper
            SC_GetMotCoggCmdPrm_Oper: operation=GetMotCoggCmdPrm.Oper
            SC_GetMotPrmNomEol_Oper: operation=GetMotPrmNomEol.Oper
            SC_GetMotRplCoggPrm_Oper: operation=GetMotRplCoggPrm.Oper
            SC_GetMotTqCmdSca_Oper: operation=GetMotTqCmdSca.Oper
            SC_GetNtcSts_Oper: operation=GetNtcSts.Oper
            SC_GetPullCmpPrm_Oper: operation=GetPullCmpPrm.Oper
            SC_GetRefTmr100MicroSec32bit1_Oper: operation=GetRefTmr100MicroSec32bit1.Oper
            SC_GetTiSpan100MicroSec32bit1_Oper: operation=GetTiSpan100MicroSec32bit1.Oper
            SC_GetYawRateOffs_Oper: operation=GetYawRateOffs.Oper
            SC_HwAg0ClrLtch_Oper: operation=HwAg0ClrLtch.Oper
            SC_HwAg0MeasHwAg0AutoTrim1_Oper: operation=HwAg0MeasHwAg0AutoTrim.Oper
            SC_HwAg0MeasHwAg0ClrTrim1_Oper: operation=HwAg0MeasHwAg0ClrTrim.Oper
            SC_HwAg0MeasHwAg0ReadTrim2_Oper: operation=HwAg0MeasHwAg0ReadTrim.Oper
            SC_HwAg0MeasHwAg0TrimPrfmdSts2_Oper: operation=HwAg0MeasHwAg0TrimPrfmdSts.Oper
            SC_HwAg0MeasHwAg0WrTrim2_Oper: operation=HwAg0MeasHwAg0WrTrim.Oper
            SC_HwAg1ClrLtch_Oper: operation=HwAg1ClrLtch.Oper
            SC_HwAg1MeasHwAg1AutoTrim1_Oper: operation=HwAg1MeasHwAg1AutoTrim.Oper
            SC_HwAg1MeasHwAg1ClrTrim1_Oper: operation=HwAg1MeasHwAg1ClrTrim.Oper
            SC_HwAg1MeasHwAg1ReadTrim2_Oper: operation=HwAg1MeasHwAg1ReadTrim.Oper
            SC_HwAg1MeasHwAg1TrimPrfmdSts2_Oper: operation=HwAg1MeasHwAg1TrimPrfmdSts.Oper
            SC_HwAg1MeasHwAg1WrTrim2_Oper: operation=HwAg1MeasHwAg1WrTrim.Oper
            SC_HwTq0MeasHwTq0AutTrim_Oper: operation=HwTq0MeasHwTq0AutTrim.Oper
            SC_HwTq0MeasHwTq0ClrTrim_Oper: operation=HwTq0MeasHwTq0ClrTrim.Oper
            SC_HwTq0MeasHwTq0ReadTrim_Oper: operation=HwTq0MeasHwTq0ReadTrim.Oper
            SC_HwTq0MeasHwTq0TrimPrfmdSts_Oper: operation=HwTq0MeasHwTq0TrimPrfmdSts.Oper
            SC_HwTq0MeasHwTq0WrTrim_Oper: operation=HwTq0MeasHwTq0WrTrim.Oper
            SC_HwTq1MeasHwTq1AutTrim_Oper: operation=HwTq1MeasHwTq1AutTrim.Oper
            SC_HwTq1MeasHwTq1ClrTrim_Oper: operation=HwTq1MeasHwTq1ClrTrim.Oper
            SC_HwTq1MeasHwTq1ReadTrim_Oper: operation=HwTq1MeasHwTq1ReadTrim.Oper
            SC_HwTq1MeasHwTq1TrimPrfmdSts_Oper: operation=HwTq1MeasHwTq1TrimPrfmdSts.Oper
            SC_HwTq1MeasHwTq1WrTrim_Oper: operation=HwTq1MeasHwTq1WrTrim.Oper
            SC_HwTq2MeasHwTq2AutTrim_Oper: operation=HwTq2MeasHwTq2AutTrim.Oper
            SC_HwTq2MeasHwTq2ClrTrim_Oper: operation=HwTq2MeasHwTq2ClrTrim.Oper
            SC_HwTq2MeasHwTq2ReadTrim_Oper: operation=HwTq2MeasHwTq2ReadTrim.Oper
            SC_HwTq2MeasHwTq2TrimPrfmdSts_Oper: operation=HwTq2MeasHwTq2TrimPrfmdSts.Oper
            SC_HwTq2MeasHwTq2WrTrim_Oper: operation=HwTq2MeasHwTq2WrTrim.Oper
            SC_HwTq3MeasHwTq3AutTrim_Oper: operation=HwTq3MeasHwTq3AutTrim.Oper
            SC_HwTq3MeasHwTq3ClrTrim_Oper: operation=HwTq3MeasHwTq3ClrTrim.Oper
            SC_HwTq3MeasHwTq3ReadTrim_Oper: operation=HwTq3MeasHwTq3ReadTrim.Oper
            SC_HwTq3MeasHwTq3TrimPrfmdSts_Oper: operation=HwTq3MeasHwTq3TrimPrfmdSts.Oper
            SC_HwTq3MeasHwTq3WrTrim_Oper: operation=HwTq3MeasHwTq3WrTrim.Oper
            SC_HwTq4AutTrim_Oper: operation=HwTq4AutTrim.Oper
            SC_HwTq4ClrSnsrSca_Oper: operation=HwTq4ClrSnsrSca.Oper
            SC_HwTq4ClrTrim_Oper: operation=HwTq4ClrTrim.Oper
            SC_HwTq4ReadSnsrSca_Oper: operation=HwTq4ReadSnsrSca.Oper
            SC_HwTq4ReadTrim_Oper: operation=HwTq4ReadTrim.Oper
            SC_HwTq4SnsrScaPrfmdSts_Oper: operation=HwTq4SnsrScaPrfmdSts.Oper
            SC_HwTq4TrimPrfmdSts_Oper: operation=HwTq4TrimPrfmdSts.Oper
            SC_HwTq4WrSnsrSca_Oper: operation=HwTq4WrSnsrSca.Oper
            SC_HwTq4WrTrim_Oper: operation=HwTq4WrTrim.Oper
            SC_HwTq5AutTrim_Oper: operation=HwTq5AutTrim.Oper
            SC_HwTq5ClrSnsrSca_Oper: operation=HwTq5ClrSnsrSca.Oper
            SC_HwTq5ClrTrim_Oper: operation=HwTq5ClrTrim.Oper
            SC_HwTq5ReadSnsrSca_Oper: operation=HwTq5ReadSnsrSca.Oper
            SC_HwTq5ReadTrim_Oper: operation=HwTq5ReadTrim.Oper
            SC_HwTq5SnsrScaPrfmdSts_Oper: operation=HwTq5SnsrScaPrfmdSts.Oper
            SC_HwTq5TrimPrfmdSts_Oper: operation=HwTq5TrimPrfmdSts.Oper
            SC_HwTq5WrSnsrSca_Oper: operation=HwTq5WrSnsrSca.Oper
            SC_HwTq5WrTrim_Oper: operation=HwTq5WrTrim.Oper
            SC_IgnCntrSrv_SetRamBlockStatus: operation=NvmIgnCntr.SetRamBlockStatus
            SC_InitFricLrngTbl_Oper: operation=InitFricLrngTbl.Oper
            SC_MfgEnaCntrSrv_SetRamBlockStatus: operation=NvmMfgEnaCntr.SetRamBlockStatus
            SC_MotAg0MeasMotAg0CoeffTblRead_Oper: operation=MotAg0MeasMotAg0CoeffTblRead.Oper
            SC_MotAg0MeasMotAg0CoeffTblWr_Oper: operation=MotAg0MeasMotAg0CoeffTblWr.Oper
            SC_MotAg1MeasMotAg1CoeffTblRead_Oper: operation=MotAg1MeasMotAg1CoeffTblRead.Oper
            SC_MotAg1MeasMotAg1CoeffTblWr_Oper: operation=MotAg1MeasMotAg1CoeffTblWr.Oper
            SC_MotAg5EolPrmRead_Oper: operation=MotAg5EolPrmRead.Oper
            SC_MotAg5EolPrmWr_Oper: operation=MotAg5EolPrmWr.Oper
            SC_MotAg6EolPrmRead_Oper: operation=MotAg6EolPrmRead.Oper
            SC_MotAg6EolPrmWr_Oper: operation=MotAg6EolPrmWr.Oper
            SC_MotAgCmpBackEmfRead_Oper: operation=MotAgCmpBackEmfRead.Oper
            SC_MotAgCmpBackEmfWr_Oper: operation=MotAgCmpBackEmfWr.Oper
            SC_MotAgMeasEolPrmRead_Oper_1: operation=MotAgMeasEolPrmRead.Oper
            SC_MotAgMeasEolPrmWr_Oper_1: operation=MotAgMeasEolPrmWr.Oper
            SC_NvmCcaHwPartNr_SetRamBlockStatus: operation=NvmCcaHwPartNr.SetRamBlockStatus
            SC_NvmCcaSerlNr_SetRamBlockStatus: operation=NvmCcaSerlNr.SetRamBlockStatus
            SC_NvmDiRestore_SetRamBlockStatus: operation=NvmDiRestore.SetRamBlockStatus
            SC_NvmEpsSysSerlNr_SetRamBlockStatus: operation=NvmEpsSysSerlNr.SetRamBlockStatus
            SC_NvmMfgTmpBuf{0..4}_SetRamBlockStatus: operation=NvmMfgTmpBuf{0..4}.SetRamBlockStatus
            SC_NvmSeedKey_EraseBlock: operation=NvmSeedKey.EraseBlock
            SC_NvmSeedKey_GetErrorStatus: operation=NvmSeedKey.GetErrorStatus
            SC_NvmSeedKey_SetRamBlockStatus: operation=NvmSeedKey.SetRamBlockStatus
            SC_NxtrCalIdsCalDevlpRd_Oper: operation=NxtrCalIdsCalDevlpRd.Oper
            SC_NxtrCalIdsCalRelRd_Oper: operation=NxtrCalIdsCalRelRd.Oper
            SC_NxtrSwIdsPsrInfoRd_Oper: operation=NxtrSwIdsPsrInfoRd.Oper
            SC_NxtrSwIdsSwBuildDateTiRd_Oper: operation=NxtrSwIdsSwBuildDateTiRd.Oper
            SC_NxtrSwIdsSwRelNrRd_Oper: operation=NxtrSwIdsSwRelNrRd.Oper
            SC_NxtrSwIdsSwRelVerRd_Oper: operation=NxtrSwIdsSwRelVerRd.Oper
            SC_NxtSwIdsSwRelInfoRd_Oper: operation=NxtrSwIdsSwRelInfoRd.Oper
            SC_PolarityCfgRead_Oper: operation=PolarityCfgRead.Oper
            SC_PolarityCfgWr_Oper: operation=PolarityCfgWr.Oper
            SC_ReadExtdSnpshtData_Oper: operation=ReadExtdSnpshtData.Oper
            SC_ReadLtchCntrData_Oper: operation=ReadLtchCntrData.Oper
            SC_ReadNtcFltAry_Oper: operation=ReadNtcFltAry.Oper
            SC_ReadNtcInfoAndDebCntr_Oper: operation=ReadNtcInfoAndDebCntr.Oper
            SC_ReadSnpshtData_Oper: operation=ReadSnpshtData.Oper
            SC_RstHwAgOverTrvlCnt_Oper: operation=RstHwAgOverTrvlCnt.Oper
            SC_RstHwTq_Oper: operation=RstHwTq.Oper
            SC_RstMaxHwAgCwAndCcw_Oper: operation=RstMaxHwAgCwAndCcw.Oper
            SC_RstPullCmp_Oper: operation=RstPullCmp.Oper
            SC_RstSnsrlsHwCentr_Oper: operation=RstSnsrlsHwCentr.Oper
            SC_RstYawAndAg_Oper: operation=RstYawAndAg.Oper
            SC_RtnMaxHwAgCwAndCcw_Oper: operation=RtnMaxHwAgCwAndCcw.Oper
            SC_SerlComRstEot_Oper: operation=SerlComRstEot.Oper
            SC_SetCtrlPrm_Oper: operation=SetCtrlPrm.Oper
            SC_SetFricData_Oper: operation=SetFricData.Oper
            SC_SetFricLrngData_Oper: operation=SetFricLrngData.Oper
            SC_SetFricOffsOutpDi_Oper: operation=SetFricOffsOutpDi.Oper
            SC_SetHwAgOffs_Oper: operation=SetHwAgOffs.Oper
            SC_SetHwAgOverTrvlCnt_Oper: operation=SetHwAgOverTrvlCnt.Oper
            SC_SetHwAgTrimVal_Oper_1: operation=SetHwAgTrimVal.Oper
            SC_SetHwTqOffs_Oper: operation=SetHwTqOffs.Oper
            SC_SetManTqCmd_Oper: operation=SetManTqCmd.Oper
            SC_SetMotCoggCmdPrm_Oper: operation=SetMotCoggCmdPrm.Oper
            SC_SetMotPrmNomEol_Oper: operation=SetMotPrmNomEol.Oper
            SC_SetMotRplCoggPrm_Oper: operation=SetMotRplCoggPrm.Oper
            SC_SetMotTqCmdSca_Oper: operation=SetMotTqCmdSca.Oper
            SC_SetPullCmpLongTerm_Oper: operation=SetPullCmpLongTerm.Oper
            SC_SetPullCmpShoTerm_Oper: operation=SetPullCmpShoTerm.Oper
            SC_SetYawRateOffs_Oper: operation=SetYawRateOffs.Oper
            SC_StackMeasClr_Oper: operation=StackMeasClr.Oper
            SC_StackMeasRead_Operation: operation=StackMeasRead.Operation
            SC_StopCtrl_Oper: operation=StopCtrl.Oper
            SC_StrtCtrl_Oper: operation=StrtCtrl.Oper
            SC_SwCalGetPrm_Oper: operation=SwCalGetPrm.Oper
            SC_SwCalSetPrm_Oper: operation=SwCalSetPrm.Oper
            SC_SwCalStop_Oper: operation=SwCalStop.Oper
            SC_SwCalStrt_Oper: operation=SwCalStrt.Oper
            SC_UpdErrInjReg_PortIf1_Oper: operation=UpdErrInjReg.Oper
            SC_UpdHwAgTrimVal_Oper: operation=UpdHwAgTrimVal.Oper
        CmnMfgSrvInit1
          data-send-points:
            access SEND_IgnCntr_Val_1: accessed-variable=IgnCntr.Val
            access SEND_MfgEnaSt_Val: accessed-variable=MfgEnaSt.Val
          sync call SC_CmnMfgSrvIfCmnMfgSrvIfImdtTx_Oper: operation=CmnMfgSrvIfCmnMfgSrvIfImdtTx.Oper, timeout=0
          sync call SC_IgnCntrSrv_SetRamBlockStatus: operation=NvmIgnCntr.SetRamBlockStatus, timeout=0
          sync call SC_MfgEnaCntrSrv_SetRamBlockStatus: operation=NvmMfgEnaCntr.SetRamBlockStatus, timeout=0
        CmnMfgSrvPer1
          data-receive-point-by-arguments:
            21 x access:
              REC_BrdgVltg_Val: accessed-variable=BrdgVltg.Val
              REC_EcuTFild_Val: accessed-variable=EcuTFild.Val
              REC_HwAg_Val: accessed-variable=HwAg.Val
              REC_HwAg0_Val: accessed-variable=HwAg0.Val
              REC_HwAg1_Val: accessed-variable=HwAg1.Val
              REC_HwTq_Val: accessed-variable=HwTq.Val
              REC_HwTq{0..3}_Val: accessed-variable=HwTq{0..3}.Val
              REC_MotAg{0..2}Mecl_Val: accessed-variable=MotAg{0..2}Mecl.Val
              REC_MotAgCumvAlgndMrf_Val: accessed-variable=MotAgCumvAlgndMrf.Val
              REC_MotAgMecl_Val: accessed-variable=MotAgMecl.Val
              REC_MotCurrDax_Val: accessed-variable=MotCurrDax.Val
              REC_MotCurrQax_Val: accessed-variable=MotCurrQax.Val
              REC_MotTqCmd_Val: accessed-variable=MotTqCmd.Val
              REC_MotVelMrf_Val: accessed-variable=MotVelMrf.Val
              REC_PinionAg_Val: accessed-variable=PinionAg.Val
              REC_SysSt_Val: accessed-variable=SysSt.Val
          data-send-points:
            15 x access:
              SEND_AssiMechTEstimnDi_Logl: accessed-variable=AssiMechTEstimnDi.Logl
              SEND_DampgCmdBasDi_Logl: accessed-variable=DampgCmdBasDi.Logl
              SEND_DutyCycThermProtnDi_Logl: accessed-variable=DutyCycThermProtnDi.Logl
              SEND_EotProtnDi_Logl: accessed-variable=EotProtnDi.Logl
              SEND_FricLrngDi_Logl: accessed-variable=FricLrngDi.Logl
              SEND_HysCmpCmdDi_Logl: accessed-variable=HysCmpCmdDi.Logl
              SEND_InertiaCmpVelCmdDi_Logl: accessed-variable=InertiaCmpVelCmdDi.Logl
              SEND_LoaScaDi_Logl: accessed-variable=LoaScaDi.Logl
              SEND_MfgDiagcInhb_Logl: accessed-variable=MfgDiagcInhb.Logl
              SEND_PullCmpCmdDi_Logl: accessed-variable=PullCmpCmdDi.Logl
              SEND_PullCmpLrngDi_Logl: accessed-variable=PullCmpLrngDi.Logl
              SEND_RtnCmdDi_Logl: accessed-variable=RtnCmdDi.Logl
              SEND_StallMotTqLimDi_Logl: accessed-variable=StallMotTqLimDi.Logl
              SEND_SysMotTqCmdRampRateDi_Logl: accessed-variable=SysMotTqCmdRampRateDi.Logl
              SEND_SysStReqEnaOvrd_Logl: accessed-variable=SysStReqEnaOvrd.Logl
          sync call SC_GetTiSpan100MicroSec32bit1_Oper: operation=GetTiSpan100MicroSec32bit1.Oper, timeout=0
          sync call SC_SetManTqCmd_Oper: operation=SetManTqCmd.Oper, timeout=0
        SwCalStsCallBack_Oper
          sync call SC_CmnMfgSrvIfCmnMfgSrvIfImdtTx_Oper: operation=CmnMfgSrvIfCmnMfgSrvIfImdtTx.Oper, timeout=0
      12 x swc service dependency:
        NvmCcaHwPartNr: assigned-datas=role-based-data-assignment={role=ramBlock, used-data-element=CcaHwPartNr}, assigned-ports=role-based-port-assignment={port-prototype=NvmCcaHwPartNr, role=NvMService_AC3_SRBS}
          service-needs:
            nv block needs NvmCcaHwPartNr: n-data-sets=0, readonly=false, reliability=NO-PROTECTION, resistant-to-changed-sw=true, restore-at-start=true, store-at-shutdown=true, write-only-once=false, writing-frequency=0, writing-priority=LOW
        NvmCcaSerlNr: assigned-datas=role-based-data-assignment={role=ramBlock, used-data-element=CcaSerlNr}, assigned-ports=role-based-port-assignment={port-prototype=NvmCcaSerlNr, role=NvMService_AC3_SRBS}
          service-needs:
            nv block needs NvmCcaSerlNr: n-data-sets=0, readonly=false, reliability=NO-PROTECTION, resistant-to-changed-sw=true, restore-at-start=true, store-at-shutdown=true, write-only-once=false, writing-frequency=0, writing-priority=LOW
        NvmDiRestore: assigned-datas=role-based-data-assignment={role=ramBlock, used-data-element=DiRestore}, assigned-ports=role-based-port-assignment={port-prototype=NvmDiRestore, role=NvMService_AC3_SRBS}
          service-needs:
            nv block needs NvmDiRestore: n-data-sets=0, readonly=false, reliability=NO-PROTECTION, resistant-to-changed-sw=true, restore-at-start=true, store-at-shutdown=true, write-only-once=false, writing-frequency=0, writing-priority=LOW
        NvmEpsSysSerlNr: assigned-datas=role-based-data-assignment={role=ramBlock, used-data-element=EpsSysSerlNr}, assigned-ports=role-based-port-assignment={port-prototype=NvmEpsSysSerlNr, role=NvMService_AC3_SRBS}
          service-needs:
            nv block needs NvmEpsSysSerlNr: n-data-sets=0, readonly=false, reliability=NO-PROTECTION, resistant-to-changed-sw=true, restore-at-start=true, store-at-shutdown=true, write-only-once=false, writing-frequency=0, writing-priority=LOW
        NvmIgnCntr: assigned-ports=role-based-port-assignment={port-prototype=NvmIgnCntr, role=NvMService_AC3_SRBS}
          assigned-datas:
            role=ramBlock, used-data-element=IgnCntr
            role=defaultValue, used-parameter-element=NvmIgnCntr_DefaultValue
          service-needs:
            nv block needs NvmIgnCntr: n-data-sets=0, readonly=false, reliability=NO-PROTECTION, resistant-to-changed-sw=true, restore-at-start=true, store-at-shutdown=true, write-only-once=false, writing-frequency=0, writing-priority=LOW
        NvmMfgEnaCntr: assigned-ports=role-based-port-assignment={port-prototype=NvmMfgEnaCntr, role=NvMService_AC3_SRBS}
          assigned-datas:
            role=ramBlock, used-data-element=NxtrMfgEnaCntr
            role=defaultValue, used-parameter-element=NvmMfgEnaCntr_DefaultValue
          service-needs:
            nv block needs NvmMfgEnaCntr: n-data-sets=0, readonly=false, reliability=NO-PROTECTION, resistant-to-changed-sw=true, restore-at-start=true, store-at-shutdown=true, write-only-once=false, writing-frequency=0, writing-priority=LOW
        NvmMfgTmpBuf0: assigned-datas=role-based-data-assignment={role=ramBlock, used-data-element=MfgTmpBuf0}, assigned-ports=role-based-port-assignment={port-prototype=NvmMfgTmpBuf0, role=NvMService_AC3_SRBS}
          service-needs:
            nv block needs NvmMfgTmpBuf0: n-data-sets=0, readonly=false, reliability=NO-PROTECTION, resistant-to-changed-sw=true, restore-at-start=true, store-at-shutdown=true, write-only-once=false, writing-frequency=0, writing-priority=LOW
        NvmMfgTmpBuf1: assigned-datas=role-based-data-assignment={role=ramBlock, used-data-element=MfgTmpBuf1}, assigned-ports=role-based-port-assignment={port-prototype=NvmMfgTmpBuf1, role=NvMService_AC3_SRBS}
          service-needs:
            nv block needs NvmMfgTmpBuf1: n-data-sets=0, readonly=false, reliability=NO-PROTECTION, resistant-to-changed-sw=true, restore-at-start=true, store-at-shutdown=true, write-only-once=false, writing-frequency=0, writing-priority=LOW
        NvmMfgTmpBuf2: assigned-datas=role-based-data-assignment={role=ramBlock, used-data-element=MfgTmpBuf2}, assigned-ports=role-based-port-assignment={port-prototype=NvmMfgTmpBuf2, role=NvMService_AC3_SRBS}
          service-needs:
            nv block needs NvmMfgTmpBuf2: n-data-sets=0, readonly=false, reliability=NO-PROTECTION, resistant-to-changed-sw=true, restore-at-start=true, store-at-shutdown=true, write-only-once=false, writing-frequency=0, writing-priority=LOW
        NvmMfgTmpBuf3: assigned-datas=role-based-data-assignment={role=ramBlock, used-data-element=MfgTmpBuf3}, assigned-ports=role-based-port-assignment={port-prototype=NvmMfgTmpBuf3, role=NvMService_AC3_SRBS}
          service-needs:
            nv block needs NvmMfgTmpBuf3: n-data-sets=0, readonly=false, reliability=NO-PROTECTION, resistant-to-changed-sw=true, restore-at-start=true, store-at-shutdown=true, write-only-once=false, writing-frequency=0, writing-priority=LOW
        NvmMfgTmpBuf4: assigned-datas=role-based-data-assignment={role=ramBlock, used-data-element=MfgTmpBuf4}, assigned-ports=role-based-port-assignment={port-prototype=NvmMfgTmpBuf4, role=NvMService_AC3_SRBS}
          service-needs:
            nv block needs NvmMfgTmpBuf4: n-data-sets=0, readonly=false, reliability=NO-PROTECTION, resistant-to-changed-sw=true, restore-at-start=true, store-at-shutdown=true, write-only-once=false, writing-frequency=0, writing-priority=LOW
        NvmSeedKey: assigned-datas=[{role=ramBlock, used-data-element=SeedKey}, {role=defaultValue, used-parameter-element=SeedKeyDft}], assigned-ports=role-based-port-assignment={port-prototype=NvmSeedKey, role=NvMService_AC3_SRBS_Defs}
          service-needs:
            nv block needs NvmSeedKey: n-data-sets=0, reliability=NO-PROTECTION, resistant-to-changed-sw=true, restore-at-start=true, store-at-shutdown=true
      shared-parameters:
        4 x parameter data prototype, all with sw-calibration-access=READ-WRITE:
          NvmIgnCntr_DefaultValue: type=uint32, init-value=0
          NvmMfgEnaCntr_DefaultValue: type=uint8, init-value=254
          NvmNxtrSeedKey_DefaultValue: type=Ary1D_u8_10, init-value=[1, 2, 3, 4, 5, 254, 253, 252, 251, 250]
          SeedKeyDft: type=Ary1D_u32_2, init-value=[19088743, 2309737967]
  swc implementation CmnMfgSrv_Implementation: behavior=CmnMfgSrv_InternalBehavior
    code-descriptors:
      code Default: artifact-descriptors=autosar-engineering-object={short-label=Default, category=SWSRC}
